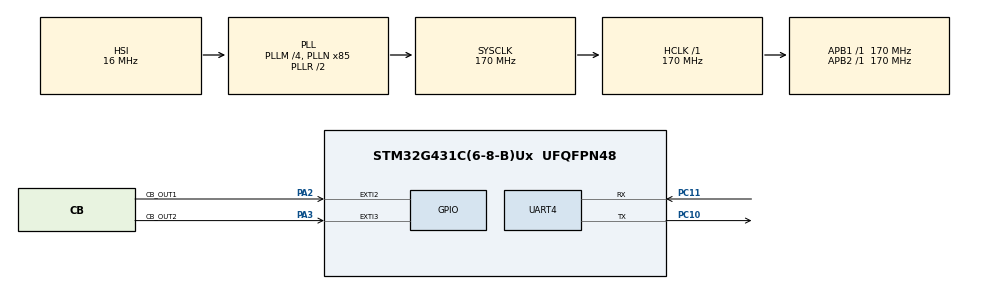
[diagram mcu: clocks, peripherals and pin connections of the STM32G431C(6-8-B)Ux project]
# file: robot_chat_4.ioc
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FREERTOS.Tasks01=defaultTask,24,128,StartDefaultTask,Default,NULL,Dynamic,NULL,NULL
Mcu.Family=STM32G4
Mcu.Name=STM32G431C(6-8-B)Ux
Mcu.Package=UFQFPN48
NVIC.EXTI2_IRQn=true\:5\:0\:false\:false\:true\:true\:true\:true\:true
NVIC.EXTI3_IRQn=true\:5\:0\:false\:false\:true\:true\:true\:true\:true
NVIC.PriorityGroup=NVIC_PRIORITYGROUP_4
PA13.Mode=Trace_Asynchronous_SW
PA13.Signal=SYS_JTMS-SWDIO
PA14.Mode=Trace_Asynchronous_SW
PA14.Signal=SYS_JTCK-SWCLK
PA2.GPIO_Label=CB_OUT1
PA2.GPIO_ModeDefaultEXTI=GPIO_MODE_IT_FALLING
PA2.Signal=GPXTI2
PA3.GPIO_Label=CB_OUT2
PA3.GPIO_ModeDefaultEXTI=GPIO_MODE_IT_FALLING
PA3.Signal=GPXTI3
PB3.Mode=Trace_Asynchronous_SW
PB3.Signal=SYS_JTDO-SWO
PC10.Mode=Asynchronous
PC10.Signal=UART4_TX
PC11.Mode=Asynchronous
PC11.Signal=UART4_RX
PF0-OSC_IN.Mode=HSE-External-Oscillator
PF0-OSC_IN.Signal=RCC_OSC_IN
PF1-OSC_OUT.Mode=HSE-External-Oscillator
PF1-OSC_OUT.Signal=RCC_OSC_OUT
ProjectManager.HeapSize=0x200
ProjectManager.StackSize=0x400
ProjectManager.TargetToolchain=STM32CubeIDE
RCC.ADC12Freq_Value=170000000
RCC.AHBFreq_Value=170000000
RCC.APB1Freq_Value=170000000
RCC.APB1TimFreq_Value=170000000
RCC.APB2Freq_Value=170000000
RCC.APB2TimFreq_Value=170000000
RCC.CortexFreq_Value=170000000
RCC.EXTERNAL_CLOCK_VALUE=12288000
RCC.HCLKFreq_Value=170000000
RCC.HSE_VALUE=8000000
RCC.HSI48_VALUE=48000000
RCC.HSI_VALUE=16000000
RCC.LSE_VALUE=32768
RCC.PLLM=RCC_PLLM_DIV4
RCC.PLLN=85
RCC.SYSCLKFreq_VALUE=170000000
RCC.SYSCLKSource=RCC_SYSCLKSOURCE_PLLCLK
RCC.USBFreq_Value=170000000
RCC.VCOOutputFreq_Value=340000000
VP_FREERTOS_VS_CMSIS_V2.Mode=CMSIS_V2
VP_SYS_VS_DBSignals.Mode=DisableDeadBatterySignals
board=custom

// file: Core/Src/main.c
/* USER CODE BEGIN Header */
/**
  ******************************************************************************
  * @file           : main.c
  * @brief          : Main program body
  ******************************************************************************
  * @attention
  *
  * Copyright (c) 2024 STMicroelectronics.
  * All rights reserved.
  *
  * This software is licensed under terms that can be found in the LICENSE file
  * in the root directory of this software component.
  * If no LICENSE file comes with this software, it is provided AS-IS.
  *
  ******************************************************************************
  */
/* USER CODE END Header */
#include "main.h"
#include "cmsis_os.h"
#include "usart.h"
#include "gpio.h"

/* USER CODE BEGIN Includes */
#include "stdio.h"
#include "Moustache.h"
/* USER CODE END Includes */

void SystemClock_Config(void);
void MX_FREERTOS_Init(void);

/* USER CODE BEGIN 0 */

int __io_putchar(int ch) {
    HAL_UART_Transmit(&huart4, (uint8_t *)&ch, 1, HAL_MAX_DELAY);
    return ch;
}

/* USER CODE END 0 */

int main(void)
{

  /* MCU Configuration--------------------------------------------------------*/

  /* Reset of all peripherals, Initializes the Flash interface and the Systick. */
  HAL_Init();

  /* USER CODE BEGIN Init */
  Moustache_Init(); // Initialisation du driver
  /* USER CODE END Init */

  /* Configure the system clock */
  SystemClock_Config();

  /* Initialize all configured peripherals */
  MX_GPIO_Init();
  MX_UART4_Init();
  /* USER CODE BEGIN 2 */
  printf("---- FreeRTOS Demo ----\r\n");

  // Initialisation de Moustache
  Moustache_Init();

  /* USER CODE END 2 */

  /* Init scheduler */
  osKernelInitialize();

  /* Call init function for freertos objects (in cmsis_os2.c) */
  MX_FREERTOS_Init();

  /* Start scheduler */
  osKernelStart();

  /* We should never get here as control is now taken by the scheduler */

  /* Infinite loop */
  while (1)
  {

  }
}

void SystemClock_Config(void)
{
  RCC_OscInitTypeDef RCC_OscInitStruct = {0};
  RCC_ClkInitTypeDef RCC_ClkInitStruct = {0};

  /** Configure the main internal regulator output voltage
  */
  HAL_PWREx_ControlVoltageScaling(PWR_REGULATOR_VOLTAGE_SCALE1_BOOST);

  /** Initializes the RCC Oscillators according to the specified parameters
  * in the RCC_OscInitTypeDef structure.
  */
  RCC_OscInitStruct.OscillatorType = RCC_OSCILLATORTYPE_HSI;
  RCC_OscInitStruct.HSIState = RCC_HSI_ON;
  RCC_OscInitStruct.HSICalibrationValue = RCC_HSICALIBRATION_DEFAULT;
  RCC_OscInitStruct.PLL.PLLState = RCC_PLL_ON;
  RCC_OscInitStruct.PLL.PLLSource = RCC_PLLSOURCE_HSI;
  RCC_OscInitStruct.PLL.PLLM = RCC_PLLM_DIV4;
  RCC_OscInitStruct.PLL.PLLN = 85;
  RCC_OscInitStruct.PLL.PLLP = RCC_PLLP_DIV2;
  RCC_OscInitStruct.PLL.PLLQ = RCC_PLLQ_DIV2;
  RCC_OscInitStruct.PLL.PLLR = RCC_PLLR_DIV2;
  if (HAL_RCC_OscConfig(&RCC_OscInitStruct) != HAL_OK)
  {
    Error_Handler();
  }

  /** Initializes the CPU, AHB and APB buses clocks
  */
  RCC_ClkInitStruct.ClockType = RCC_CLOCKTYPE_HCLK|RCC_CLOCKTYPE_SYSCLK
                              |RCC_CLOCKTYPE_PCLK1|RCC_CLOCKTYPE_PCLK2;
  RCC_ClkInitStruct.SYSCLKSource = RCC_SYSCLKSOURCE_PLLCLK;
  RCC_ClkInitStruct.AHBCLKDivider = RCC_SYSCLK_DIV1;
  RCC_ClkInitStruct.APB1CLKDivider = RCC_HCLK_DIV1;
  RCC_ClkInitStruct.APB2CLKDivider = RCC_HCLK_DIV1;

  if (HAL_RCC_ClockConfig(&RCC_ClkInitStruct, FLASH_LATENCY_4) != HAL_OK)
  {
    Error_Handler();
  }
}

/* USER CODE BEGIN 4 */
void HAL_GPIO_EXTI_Callback(uint16_t GPIO_Pin) {
	  Moustache_HandleInterrupt(GPIO_Pin);
}

/* USER CODE END 4 */

void Error_Handler(void)
{
  __disable_irq();
  while (1)
  {
  }
}
